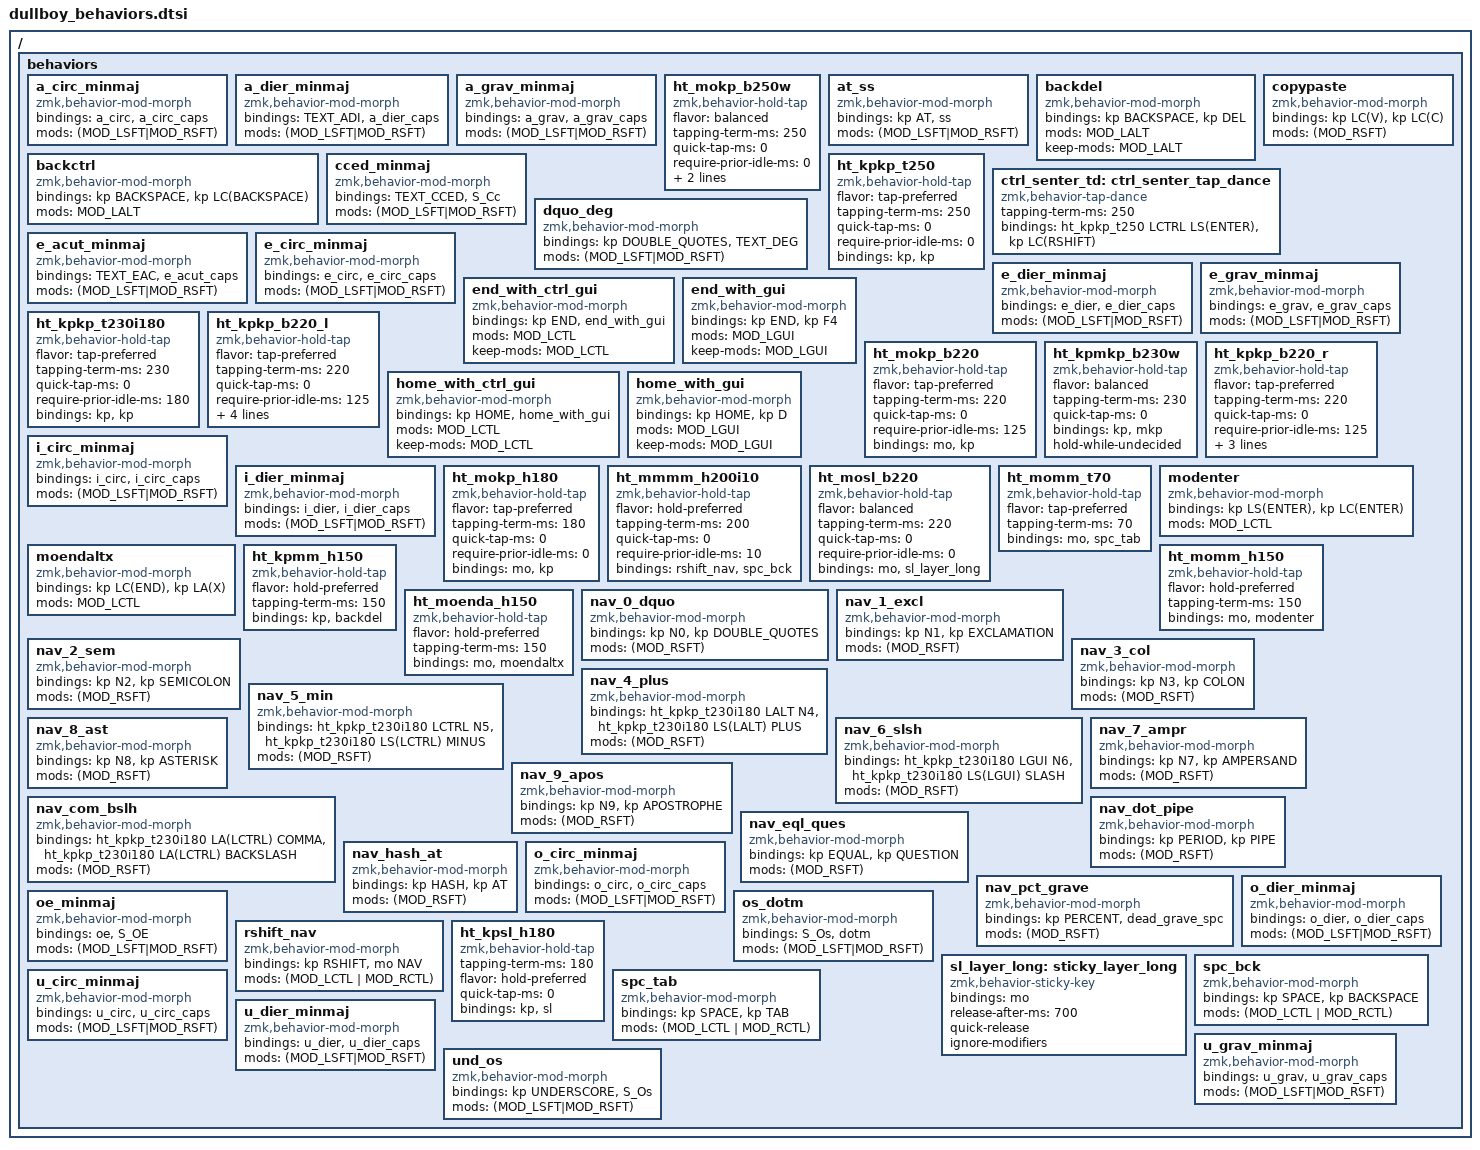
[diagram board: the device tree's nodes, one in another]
#include "layout.h"
#include "layers.h"
#include <behaviors.dtsi>
#include <dt-bindings/zmk/keys.h>
#include <dt-bindings/zmk/modifiers.h>

/* Les noms décrivent uniquement les caractéristiques :
 * ht : hold-tap
 * mo, kp, sl, mkp, mm : types de bindings
 * h, b, t : hold-preferred, balanced, tap-preferred
 * nombre : tapping-term-ms
 * i : require-prior-idle-ms
 * w : hold-while-undecided */

/ {
    behaviors {
        a_circ_minmaj: a_circ_minmaj {
            compatible = "zmk,behavior-mod-morph";
            #binding-cells = <0>;
            bindings = <&a_circ>, <&a_circ_caps>;
            mods = <(MOD_LSFT|MOD_RSFT)>;
        };

        a_dier_minmaj: a_dier_minmaj {
            compatible = "zmk,behavior-mod-morph";
            #binding-cells = <0>;
            bindings = <TEXT_ADI>, <&a_dier_caps>;
            mods = <(MOD_LSFT|MOD_RSFT)>;
        };

        a_grav_minmaj: a_grav_minmaj {
            compatible = "zmk,behavior-mod-morph";
            #binding-cells = <0>;
            bindings = <&a_grav>, <&a_grav_caps>;
            mods = <(MOD_LSFT|MOD_RSFT)>;
        };

        ht_mokp_b250w: ht_mokp_b250w {
            compatible = "zmk,behavior-hold-tap";
            #binding-cells = <2>;
            flavor = "balanced";
            tapping-term-ms = <250>;
            quick-tap-ms = <0>;
            require-prior-idle-ms = <0>;
            bindings = <&mo>, <&kp>;
            hold-while-undecided;
        };

        at_ss: at_ss {
            compatible = "zmk,behavior-mod-morph";
            #binding-cells = <0>;
            bindings = <&kp AT>, <&ss>;
            mods = <(MOD_LSFT|MOD_RSFT)>;
        };


        backdel: backdel {
            compatible = "zmk,behavior-mod-morph";
            #binding-cells = <0>;
            bindings = <&kp BACKSPACE>, <&kp DEL>;
            mods = <MOD_LALT>;
            keep-mods = <MOD_LALT>;
        };

        backctrl: backctrl {
            compatible = "zmk,behavior-mod-morph";
            #binding-cells = <0>;
            bindings = <&kp BACKSPACE>, <&kp LC(BACKSPACE)>;
            mods = <MOD_LALT>;
        };

        cced_minmaj: cced_minmaj {
            compatible = "zmk,behavior-mod-morph";
            #binding-cells = <0>;
            bindings = <TEXT_CCED>, <&S_Cc>;
            mods = <(MOD_LSFT|MOD_RSFT)>;
        };

        copypaste: copypaste {
            compatible = "zmk,behavior-mod-morph";
            #binding-cells = <0>;
            bindings = <&kp LC(V)>, <&kp LC(C)>;
            mods = <(MOD_RSFT)>;
        };

        ht_kpkp_t250: ht_kpkp_t250 {
            compatible = "zmk,behavior-hold-tap";
            #binding-cells = <2>;
            flavor = "tap-preferred";
            tapping-term-ms = <250>;
            quick-tap-ms = <0>;
            require-prior-idle-ms = <0>;
            bindings = <&kp>, <&kp>;
        };

        ctrl_senter_td: ctrl_senter_tap_dance {
            compatible = "zmk,behavior-tap-dance";
            #binding-cells = <0>;
            tapping-term-ms = <250>;
            bindings = <&ht_kpkp_t250 LCTRL LS(ENTER)>, <&kp LC(RSHIFT)>;
        };

        dquo_deg: dquo_deg {
            compatible = "zmk,behavior-mod-morph";
            #binding-cells = <0>;
            bindings = <&kp DOUBLE_QUOTES>, <TEXT_DEG>;
            mods = <(MOD_LSFT|MOD_RSFT)>;
        };

        e_acut_minmaj: e_acut_minmaj {
            compatible = "zmk,behavior-mod-morph";
            #binding-cells = <0>;
            bindings = <TEXT_EAC>, <&e_acut_caps>;
            mods = <(MOD_LSFT|MOD_RSFT)>;
        };

        e_circ_minmaj: e_circ_minmaj {
            compatible = "zmk,behavior-mod-morph";
            #binding-cells = <0>;
            bindings = <&e_circ>, <&e_circ_caps>;
            mods = <(MOD_LSFT|MOD_RSFT)>;
        };

        e_dier_minmaj: e_dier_minmaj {
            compatible = "zmk,behavior-mod-morph";
            #binding-cells = <0>;
            bindings = <&e_dier>, <&e_dier_caps>;
            mods = <(MOD_LSFT|MOD_RSFT)>;
        };

        e_grav_minmaj: e_grav_minmaj {
            compatible = "zmk,behavior-mod-morph";
            #binding-cells = <0>;
            bindings = <&e_grav>, <&e_grav_caps>;
            mods = <(MOD_LSFT|MOD_RSFT)>;
        };

        end_with_ctrl_gui: end_with_ctrl_gui {
            compatible = "zmk,behavior-mod-morph";
            #binding-cells = <0>;
            bindings = <&kp END>, <&end_with_gui>;
            mods = <MOD_LCTL>;
            keep-mods = <MOD_LCTL>;
        };

        end_with_gui: end_with_gui {
            compatible = "zmk,behavior-mod-morph";
            #binding-cells = <0>;
            bindings = <&kp END>, <&kp F4>;
            mods = <MOD_LGUI>;
            keep-mods = <MOD_LGUI>;
        };

        ht_kpkp_t230i180: ht_kpkp_t230i180 {
            compatible = "zmk,behavior-hold-tap";
            #binding-cells = <2>;
            flavor = "tap-preferred";
            tapping-term-ms = <230>;
            quick-tap-ms = <0>;
            require-prior-idle-ms = <180>;
            bindings = <&kp>, <&kp>;
        };

        ht_kpkp_b220_l: ht_kpkp_b220_l {
    compatible = "zmk,behavior-hold-tap";
    #binding-cells = <2>;

    flavor = "tap-preferred";
    tapping-term-ms = <220>;
    quick-tap-ms = <0>;
    require-prior-idle-ms = <125>;

    bindings = <&kp>, <&kp>;
            hold-trigger-key-positions = <5 6 7 8 9 15 16 17 18 19 22 25 26 27 28 29>;
            hold-trigger-on-release;
        };

        ht_mokp_b220: ht_mokp_b220 {
            compatible = "zmk,behavior-hold-tap";
            #binding-cells = <2>;
            flavor = "tap-preferred";
            tapping-term-ms = <220>;
            quick-tap-ms = <0>;
            require-prior-idle-ms = <125>;
            bindings = <&mo>, <&kp>;
        };

        ht_kpmkp_b230w: ht_kpmkp_b230w {
            compatible = "zmk,behavior-hold-tap";
            #binding-cells = <2>;
            flavor = "balanced";
            tapping-term-ms = <230>;
            quick-tap-ms = <0>;
            bindings = <&kp>, <&mkp>;
            hold-while-undecided;
        };

        ht_kpkp_b220_r: ht_kpkp_b220_r {
    compatible = "zmk,behavior-hold-tap";
    #binding-cells = <2>;

    flavor = "tap-preferred";
    tapping-term-ms = <220>;
    quick-tap-ms = <0>;
    require-prior-idle-ms = <125>;

    bindings = <&kp>, <&kp>;
            hold-trigger-key-positions = <0 1 2 3 4 10 11 12 13 14 20 20 23 24>;
        };

        home_with_ctrl_gui: home_with_ctrl_gui {
            compatible = "zmk,behavior-mod-morph";
            #binding-cells = <0>;
            bindings = <&kp HOME>, <&home_with_gui>;
            mods = <MOD_LCTL>;
            keep-mods = <MOD_LCTL>;
        };

        home_with_gui: home_with_gui {
            compatible = "zmk,behavior-mod-morph";
            #binding-cells = <0>;
            bindings = <&kp HOME>, <&kp D>;
            mods = <MOD_LGUI>;
            keep-mods = <MOD_LGUI>;
        };

        i_circ_minmaj: i_circ_minmaj {
            compatible = "zmk,behavior-mod-morph";
            #binding-cells = <0>;
            bindings = <&i_circ>, <&i_circ_caps>;
            mods = <(MOD_LSFT|MOD_RSFT)>;
        };

        i_dier_minmaj: i_dier_minmaj {
            compatible = "zmk,behavior-mod-morph";
            #binding-cells = <0>;
            bindings = <&i_dier>, <&i_dier_caps>;
            mods = <(MOD_LSFT|MOD_RSFT)>;
        };

        ht_mokp_h180: ht_mokp_h180 {
            compatible = "zmk,behavior-hold-tap";
            #binding-cells = <2>;
            flavor = "tap-preferred";
            tapping-term-ms = <180>;
            quick-tap-ms = <0>;
            require-prior-idle-ms = <0>;
            bindings = <&mo>, <&kp>;
        };

        ht_mmmm_h200i10: ht_mmmm_h200i10 {
            compatible = "zmk,behavior-hold-tap";
            #binding-cells = <2>;
            flavor = "hold-preferred";
            tapping-term-ms = <200>;
            quick-tap-ms = <0>;
            require-prior-idle-ms = <10>;
            bindings = <&rshift_nav>, <&spc_bck>;
        };

        ht_mosl_b220: ht_mosl_b220 {
            compatible = "zmk,behavior-hold-tap";
            #binding-cells = <2>;
            flavor = "balanced";
            tapping-term-ms = <220>;
            quick-tap-ms = <0>;
            require-prior-idle-ms = <0>;
            bindings = <&mo>, <&sl_layer_long>;
        };

        ht_momm_t70: ht_momm_t70 {
            compatible = "zmk,behavior-hold-tap";
            #binding-cells = <2>;
            flavor = "tap-preferred";
            tapping-term-ms = <70>;
            bindings = <&mo>, <&spc_tab>;
        };

        modenter: modenter {
            compatible = "zmk,behavior-mod-morph";
            #binding-cells = <0>;
            bindings = <&kp LS(ENTER)>, <&kp LC(ENTER)>;
            mods = <MOD_LCTL>;
        };

        moendaltx: moendaltx {
            compatible = "zmk,behavior-mod-morph";
            #binding-cells = <0>;
            bindings = <&kp LC(END)>, <&kp LA(X)>;
            mods = <MOD_LCTL>;
        };

        ht_kpmm_h150: ht_kpmm_h150 {
            compatible = "zmk,behavior-hold-tap";
            #binding-cells = <2>;
            flavor = "hold-preferred";
            tapping-term-ms = <150>;
            bindings = <&kp>, <&backdel>;
        };

        ht_momm_h150: ht_momm_h150 {
            compatible = "zmk,behavior-hold-tap";
            #binding-cells = <2>;
            flavor = "hold-preferred";
            tapping-term-ms = <150>;
            bindings = <&mo>, <&modenter>;
        };

        ht_moenda_h150: ht_moenda_h150 {
            compatible = "zmk,behavior-hold-tap";
            #binding-cells = <2>;
            flavor = "hold-preferred";
            tapping-term-ms = <150>;
            bindings = <&mo>, <&moendaltx>;
        };

        nav_0_dquo: nav_0_dquo {
            compatible = "zmk,behavior-mod-morph";
            #binding-cells = <0>;
            bindings = <&kp N0>, <&kp DOUBLE_QUOTES>;
            mods = <(MOD_RSFT)>;
        };

        nav_1_excl: nav_1_excl {
            compatible = "zmk,behavior-mod-morph";
            #binding-cells = <0>;
            bindings = <&kp N1>, <&kp EXCLAMATION>;
            mods = <(MOD_RSFT)>;
        };

        nav_2_sem: nav_2_sem {
            compatible = "zmk,behavior-mod-morph";
            #binding-cells = <0>;
            bindings = <&kp N2>, <&kp SEMICOLON>;
            mods = <(MOD_RSFT)>;
        };

        nav_3_col: nav_3_col {
            compatible = "zmk,behavior-mod-morph";
            #binding-cells = <0>;
            bindings = <&kp N3>, <&kp COLON>;
            mods = <(MOD_RSFT)>;
        };

        nav_4_plus: nav_4_plus {
            compatible = "zmk,behavior-mod-morph";
            #binding-cells = <0>;
            bindings = <&ht_kpkp_t230i180 LALT N4>, <&ht_kpkp_t230i180 LS(LALT) PLUS>;
            mods = <(MOD_RSFT)>;
        };

        nav_5_min: nav_5_min {
            compatible = "zmk,behavior-mod-morph";
            #binding-cells = <0>;
            bindings = <&ht_kpkp_t230i180 LCTRL N5>, <&ht_kpkp_t230i180 LS(LCTRL) MINUS>;
            mods = <(MOD_RSFT)>;
        };

        nav_6_slsh: nav_6_slsh {
            compatible = "zmk,behavior-mod-morph";
            #binding-cells = <0>;
            bindings = <&ht_kpkp_t230i180 LGUI N6>, <&ht_kpkp_t230i180 LS(LGUI) SLASH>;
            mods = <(MOD_RSFT)>;
        };

        nav_7_ampr: nav_7_ampr {
            compatible = "zmk,behavior-mod-morph";
            #binding-cells = <0>;
            bindings = <&kp N7>, <&kp AMPERSAND>;
            mods = <(MOD_RSFT)>;
        };

        nav_8_ast: nav_8_ast {
            compatible = "zmk,behavior-mod-morph";
            #binding-cells = <0>;
            bindings = <&kp N8>, <&kp ASTERISK>;
            mods = <(MOD_RSFT)>;
        };

        nav_9_apos: nav_9_apos {
            compatible = "zmk,behavior-mod-morph";
            #binding-cells = <0>;
            bindings = <&kp N9>, <&kp APOSTROPHE>;
            mods = <(MOD_RSFT)>;
        };

        nav_com_bslh: nav_com_bslh {
            compatible = "zmk,behavior-mod-morph";
            #binding-cells = <0>;
            bindings = <&ht_kpkp_t230i180 LA(LCTRL) COMMA>, <&ht_kpkp_t230i180 LA(LCTRL) BACKSLASH>;
            mods = <(MOD_RSFT)>;
        };

        nav_dot_pipe: nav_dot_pipe {
            compatible = "zmk,behavior-mod-morph";
            #binding-cells = <0>;
            bindings = <&kp PERIOD>, <&kp PIPE>;
            mods = <(MOD_RSFT)>;
        };

        nav_eql_ques: nav_eql_ques {
            compatible = "zmk,behavior-mod-morph";
            #binding-cells = <0>;
            bindings = <&kp EQUAL>, <&kp QUESTION>;
            mods = <(MOD_RSFT)>;
        };

        nav_hash_at: nav_hash_at {
            compatible = "zmk,behavior-mod-morph";
            #binding-cells = <0>;
            bindings = <&kp HASH>, <&kp AT>;
            mods = <(MOD_RSFT)>;
        };

        nav_pct_grave: nav_pct_grave {
            compatible = "zmk,behavior-mod-morph";
            #binding-cells = <0>;
            bindings = <&kp PERCENT>, <&dead_grave_spc>;
            mods = <(MOD_RSFT)>;
        };

        o_circ_minmaj: o_circ_minmaj {
            compatible = "zmk,behavior-mod-morph";
            #binding-cells = <0>;
            bindings = <&o_circ>, <&o_circ_caps>;
            mods = <(MOD_LSFT|MOD_RSFT)>;
        };

        o_dier_minmaj: o_dier_minmaj {
            compatible = "zmk,behavior-mod-morph";
            #binding-cells = <0>;
            bindings = <&o_dier>, <&o_dier_caps>;
            mods = <(MOD_LSFT|MOD_RSFT)>;
        };

        oe_minmaj: oe_minmaj {
            compatible = "zmk,behavior-mod-morph";
            #binding-cells = <0>;
            bindings = <&oe>, <&S_OE>;
            mods = <(MOD_LSFT|MOD_RSFT)>;
        };

        os_dotm: os_dotm {
            compatible = "zmk,behavior-mod-morph";
            #binding-cells = <0>;
            bindings = <&S_Os>, <&dotm>;
            mods = <(MOD_LSFT|MOD_RSFT)>;
        };

        rshift_nav: rshift_nav {
            compatible = "zmk,behavior-mod-morph";
            #binding-cells = <0>;
            bindings = <&kp RSHIFT>, <&mo NAV>;
            mods = <(MOD_LCTL | MOD_RCTL)>;
        };

        ht_kpsl_h180: ht_kpsl_h180 {
            compatible = "zmk,behavior-hold-tap";
            #binding-cells = <2>;
            tapping-term-ms = <180>;
            flavor = "hold-preferred";
            quick-tap-ms = <0>;
            bindings = <&kp>, <&sl>;
        };

        sl_layer_long: sticky_layer_long {
            compatible = "zmk,behavior-sticky-key";
            #binding-cells = <1>;
            bindings = <&mo>;
            release-after-ms = <700>;
            quick-release;
            ignore-modifiers;
        };

        spc_bck: spc_bck {
            compatible = "zmk,behavior-mod-morph";
            #binding-cells = <0>;
            bindings = <&kp SPACE>, <&kp BACKSPACE>;
            mods = <(MOD_LCTL | MOD_RCTL)>;
        };

        spc_tab: spc_tab {
            compatible = "zmk,behavior-mod-morph";
            #binding-cells = <0>;
            bindings = <&kp SPACE>, <&kp TAB>;
            mods = <(MOD_LCTL | MOD_RCTL)>;
        };

        u_circ_minmaj: u_circ_minmaj {
            compatible = "zmk,behavior-mod-morph";
            #binding-cells = <0>;
            bindings = <&u_circ>, <&u_circ_caps>;
            mods = <(MOD_LSFT|MOD_RSFT)>;
        };

        u_dier_minmaj: u_dier_minmaj {
            compatible = "zmk,behavior-mod-morph";
            #binding-cells = <0>;
            bindings = <&u_dier>, <&u_dier_caps>;
            mods = <(MOD_LSFT|MOD_RSFT)>;
        };

        u_grav_minmaj: u_grav_minmaj {
            compatible = "zmk,behavior-mod-morph";
            #binding-cells = <0>;
            bindings = <&u_grav>, <&u_grav_caps>;
            mods = <(MOD_LSFT|MOD_RSFT)>;
        };

        und_os: und_os {
            compatible = "zmk,behavior-mod-morph";
            #binding-cells = <0>;
            bindings = <&kp UNDERSCORE>, <&S_Os>;
            mods = <(MOD_LSFT|MOD_RSFT)>;
        };

    };
};
